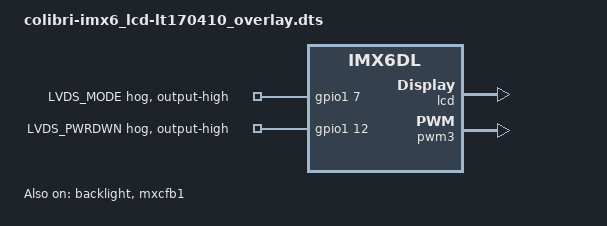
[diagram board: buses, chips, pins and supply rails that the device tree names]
// SPDX-License-Identifier: GPL-2.0-or-later OR MIT
/*
 * Copyright 2020-2021 Toradex
 */

// Enable the LCDIF interface and LVDS trasceiver, tuning settings
// for Toradex Cap LVDS 10" Display on the Colibri iMX6DL.

#include <dt-bindings/gpio/gpio.h>

/dts-v1/;
/plugin/;

/ {
	compatible = "toradex,colibri_imx6dl";
};

&backlight {
	status = "okay";
};

/* Need to be disabled due to overlapped pins SODIMM_55, SODIMM_63 */
&can1 {
	status = "disabled";
};

&gpio1 {
	/* This switches the LVDS transceiver to the single-channel
	 * output mode.
	 */
	 LVDS_MODE {
		gpio-hog;
		gpios = <7 GPIO_ACTIVE_HIGH>;
		line-name = "LVDS_MODE";
		output-high;
	};

	/* This turns the LVDS transceiver on */
	LVDS_PWRDWN {
		gpio-hog;
		gpios = <12 GPIO_ACTIVE_HIGH>;
		line-name = "LVDS_PWRDWN";
		output-high;
	};
};

&lcd {
	status = "okay";
};

&mxcfb1 {
	mode_str ="1280x800M@60";
	status = "okay";
};

&pwm3 {
	status = "okay";
};
